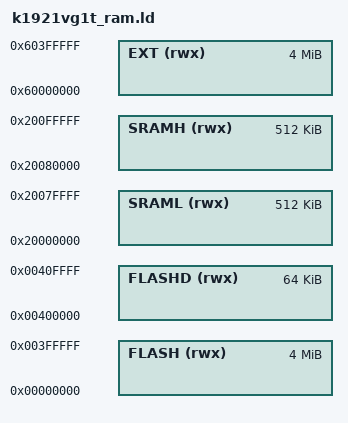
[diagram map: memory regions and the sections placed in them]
/** @file
*  @brief linker script for K1921VG1T
*/

OUTPUT_ARCH( "riscv" )
ENTRY(_start)

MEMORY {
  FLASH   (rwx) : ORIGIN = 0x00000000, LENGTH = 4096K
  FLASHD  (rwx) : ORIGIN = 0x00400000, LENGTH = 64K
  SRAML   (rwx) : ORIGIN = 0x20000000, LENGTH = 512K
  SRAMH   (rwx) : ORIGIN = 0x20080000, LENGTH = 512K
  EXT     (rwx) : ORIGIN = 0x60000000, LENGTH = 4096K
}

REGION_ALIAS("REGION_TEXT",   SRAML );
REGION_ALIAS("REGION_RODATA", SRAML );
REGION_ALIAS("REGION_DATA",   SRAMH );
REGION_ALIAS("REGION_BSS",    SRAML );
REGION_ALIAS("REGION_STACK",  SRAML );
REGION_ALIAS("REGION_DATAH",  SRAMH );
REGION_ALIAS("REGION_EXT",    EXT     );

STACK_SIZE = 2048;

INCLUDE "k1921vg1t_common.lds"
